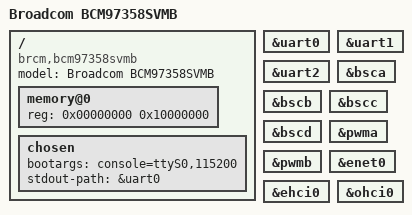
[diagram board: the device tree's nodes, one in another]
/dts-v1/;

/include/ "bcm7358.dtsi"

/ {
	compatible = "brcm,bcm97358svmb", "brcm,bcm7358";
	model = "Broadcom BCM97358SVMB";

	memory@0 {
		device_type = "memory";
		reg = <0x00000000 0x10000000>;
	};

	chosen {
		bootargs = "console=ttyS0,115200";
		stdout-path = &uart0;
	};
};

&uart0 {
	status = "okay";
};

&uart1 {
	status = "okay";
};

&uart2 {
	status = "okay";
};

&bsca {
	status = "okay";
};

&bscb {
	status = "okay";
};

&bscc {
	status = "okay";
};

&bscd {
	status = "okay";
};

&pwma {
	status = "okay";
};

&pwmb {
	status = "okay";
};

&enet0 {
	status = "okay";
};

&ehci0 {
	status = "okay";
};

&ohci0 {
	status = "okay";
};
